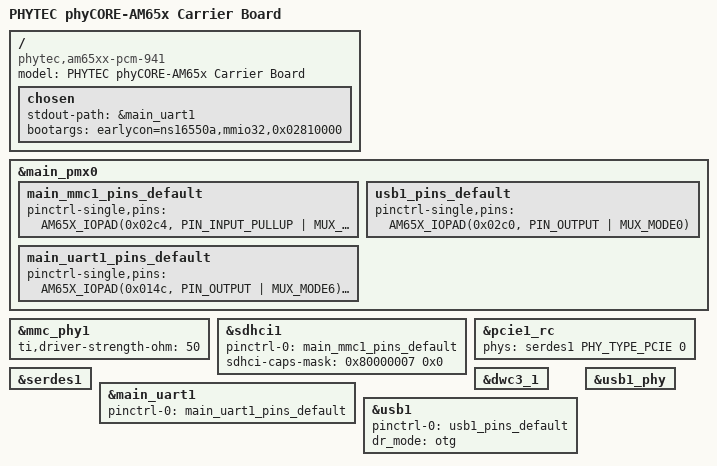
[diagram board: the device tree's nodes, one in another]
// SPDX-License-Identifier: GPL-2.0
/*
 * Copyright (C) 2018 PHYTEC America, LLC - https://www.phytec.com
 */

#include <dt-bindings/phy/phy.h>

/ {
	model = "PHYTEC phyCORE-AM65x Carrier Board";
	compatible = "phytec,am65xx-pcm-941", "phytec,am65xx-phycore-som", "ti,am654";

	chosen {
		/* UART1 as default stdout path */
		stdout-path = &main_uart1;
		bootargs = "earlycon=ns16550a,mmio32,0x02810000";
	};
};

&main_pmx0 {
	main_mmc1_pins_default: main_mmc1_pins_default {
		pinctrl-single,pins = <
			AM65X_IOPAD(0x02c4, PIN_INPUT_PULLUP | MUX_MODE0)	/* (D27) MMC1_DAT3 */
			AM65X_IOPAD(0x02c8, PIN_INPUT_PULLUP | MUX_MODE0)	/* (D26) MMC1_DAT2 */
			AM65X_IOPAD(0x02cc, PIN_INPUT_PULLUP | MUX_MODE0)	/* (E27) MMC1_DAT1 */
			AM65X_IOPAD(0x02d0, PIN_INPUT_PULLUP | MUX_MODE0)	/* (D28) MMC1_DAT0 */
			AM65X_IOPAD(0x02d4, PIN_INPUT_PULLDOWN | MUX_MODE0)	/* (C27) MMC1_CLK */
			AM65X_IOPAD(0x02d8, PIN_INPUT_PULLUP | MUX_MODE0)	/* (C28) MMC1_CMD */
			AM65X_IOPAD(0x02dc, PIN_INPUT | MUX_MODE0)		/* (B24) MMC1_SDCD */
		>;
	};

	main_uart1_pins_default: main_uart1_pins_default {
		pinctrl-single,pins = <
			AM65X_IOPAD(0x014c, PIN_OUTPUT | MUX_MODE6)	/* (AD23) PRG1_PRU1GPO6.UART1_TXD */
			AM65X_IOPAD(0x0174, PIN_INPUT | MUX_MODE6)	/* (AE23) PRG1_PRU1GPO17.UART1_RXD */
			AM65X_IOPAD(0x0178, PIN_INPUT | MUX_MODE6)	/* (AD22) PRG1_PRU1GPO18.UART1_CTS */
			AM65X_IOPAD(0x017c, PIN_OUTPUT | MUX_MODE6)	/* (AC21) PRG1_PRU1GPO19.UART1_RTS */
		>;
	};

	usb1_pins_default: usb1_pins_default {
		pinctrl-single,pins = <
			AM65X_IOPAD(0x02c0, PIN_OUTPUT | MUX_MODE0)	/* (AC8) USB1_DRVVBUS */
		>;
	};
};

&mmc_phy1 {
	status = "okay";
	ti,driver-strength-ohm = <50>;
};

&sdhci1 {
	status = "okay";
	pinctrl-names = "default";
	pinctrl-0 = <&main_mmc1_pins_default>;
	sdhci-caps-mask = <0x80000007 0x0>;
};

&pcie1_rc {
	status = "okay";
	phys = <&serdes1 PHY_TYPE_PCIE 0>;
	phy-names = "pcie-phy0";
};

&serdes1 {
	status = "okay";
};

&main_uart1 {
	status = "okay";
	pinctrl-names = "default";
	pinctrl-0 = <&main_uart1_pins_default>;
};

&dwc3_1 {
	status = "okay";
};

&usb1 {
	status = "okay";
	pinctrl-names = "default";
	pinctrl-0 = <&usb1_pins_default>;
	dr_mode = "otg";
};

&usb1_phy {
	status = "okay";
};
